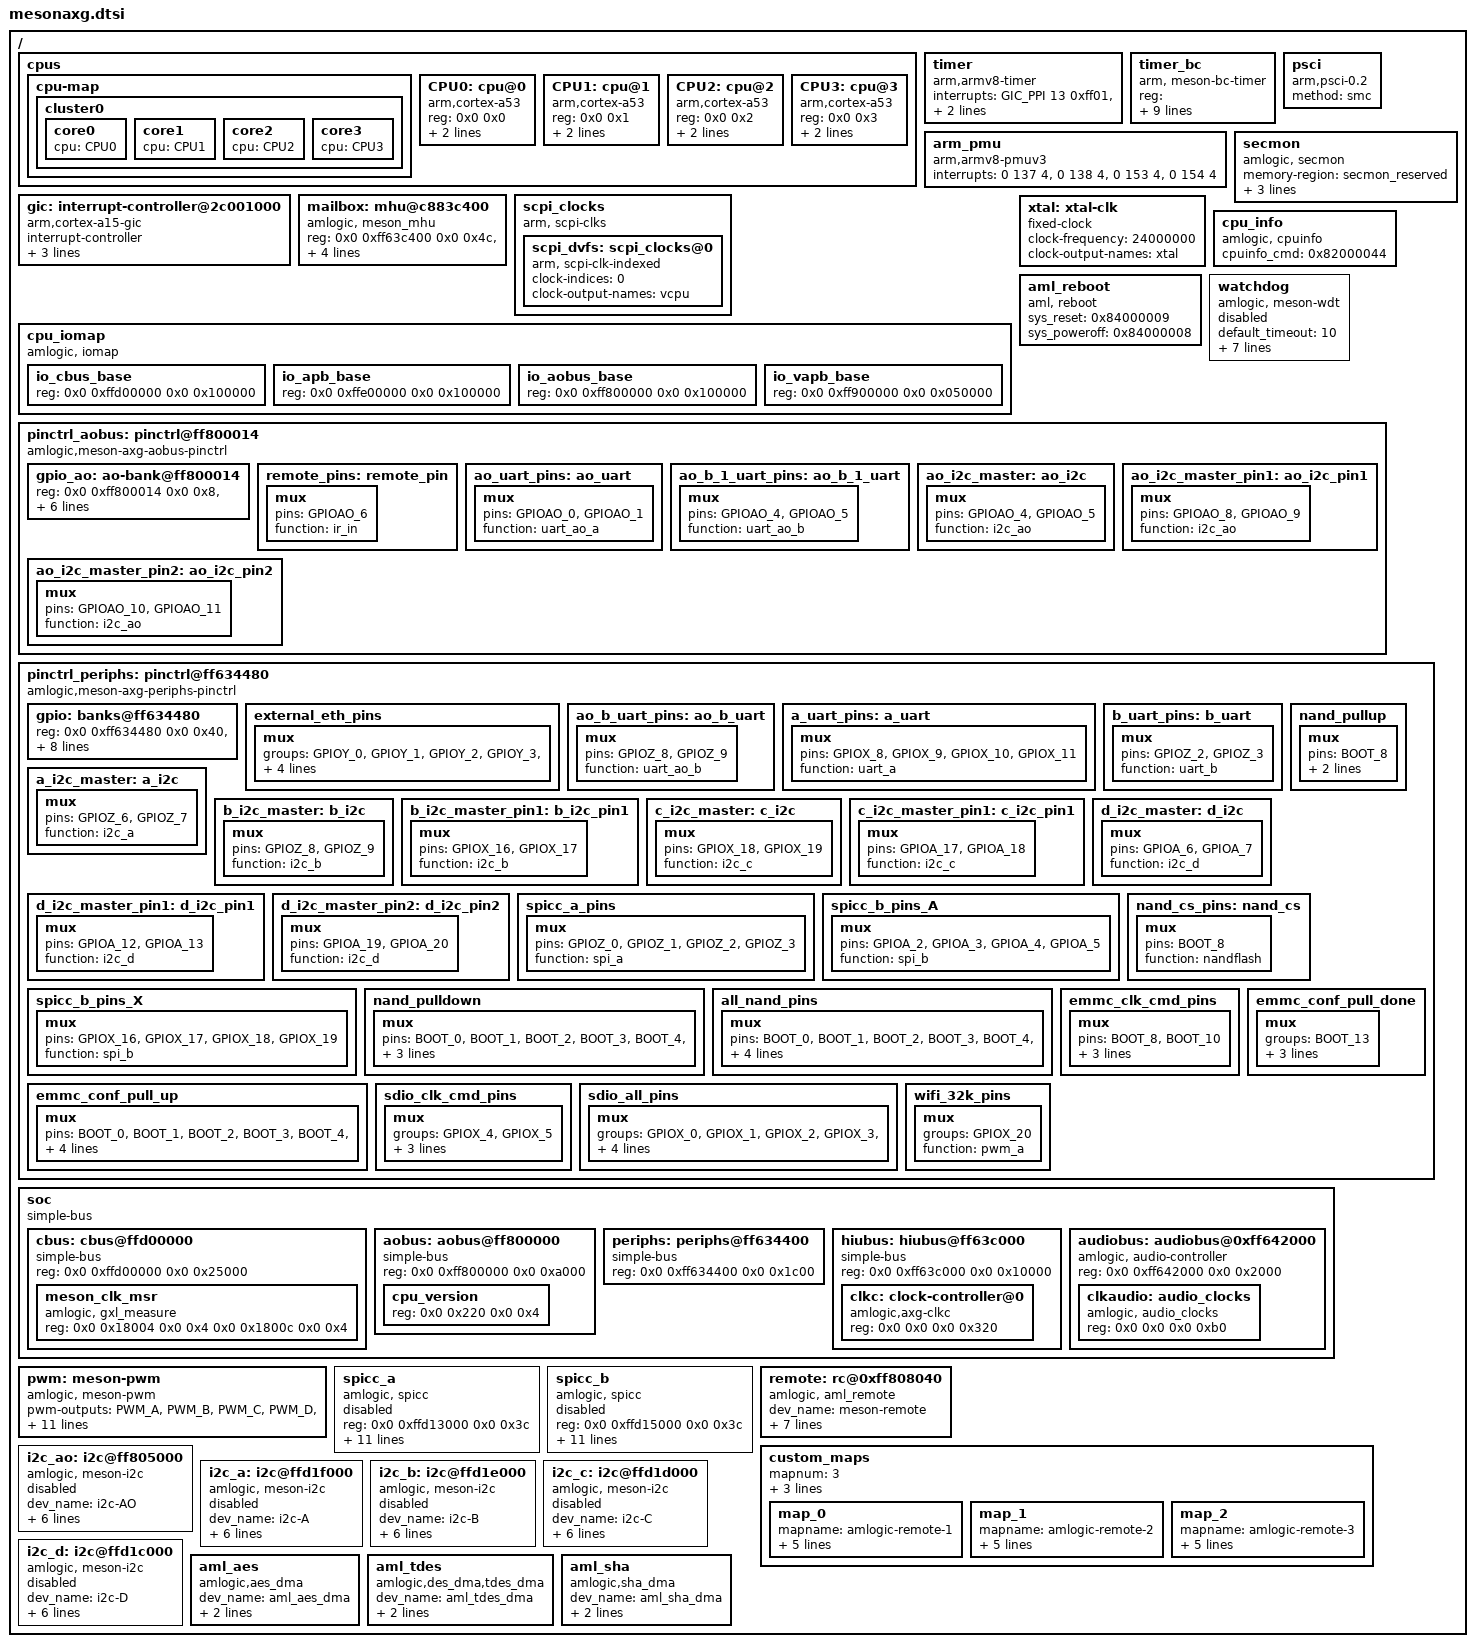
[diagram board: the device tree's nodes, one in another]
/*
 * arch/arm64/boot/dts/amlogic/mesonaxg.dtsi
 *
 * Copyright (C) 2017 Amlogic, Inc. All rights reserved.
 *
 * This program is free software; you can redistribute it and/or modify
 * it under the terms of the GNU General Public License as published by
 * the Free Software Foundation; either version 2 of the License, or
 * (at your option) any later version.
 *
 * This program is distributed in the hope that it will be useful, but WITHOUT
 * ANY WARRANTY; without even the implied warranty of MERCHANTABILITY or
 * FITNESS FOR A PARTICULAR PURPOSE.  See the GNU General Public License for
 * more details.
 *
 */

#include <dt-bindings/interrupt-controller/arm-gic.h>
#include <dt-bindings/clock/amlogic,axg-clkc.h>
#include <dt-bindings/clock/amlogic,axg-audio-clk.h>
#include <dt-bindings/gpio/mesonaxg-gpio.h>
#include <dt-bindings/pwm/pwm.h>
#include <dt-bindings/pwm/meson.h>
#include <dt-bindings/gpio/gpio.h>
#include <dt-bindings/input/input.h>
#include <dt-bindings/input/meson_rc.h>

/ {
	cpus:cpus {
		#address-cells = <2>;
		#size-cells = <0>;

		cpu-map {
			cluster0:cluster0 {
				core0 {
					cpu = <&CPU0>;
				};
				core1 {
					cpu = <&CPU1>;
				};
				core2 {
					cpu = <&CPU2>;
				};
				core3 {
					cpu = <&CPU3>;
				};
			};
		};
		CPU0:cpu@0 {
			device_type = "cpu";
			compatible = "arm,cortex-a53","arm,armv8";
			reg = <0x0 0x0>;
			enable-method = "psci";
			clocks = <&scpi_dvfs 0>;
			clock-names = "cpu-cluster.0";
			//cpu-idle-states = <&SYSTEM_SLEEP_0>;
			/*cpu-idle-states = <&CPU_SLEEP_0 &SYSTEM_SLEEP_0>;*/
		};

		CPU1:cpu@1 {
			device_type = "cpu";
			compatible = "arm,cortex-a53","arm,armv8";
			reg = <0x0 0x1>;
			enable-method = "psci";
			clocks = <&scpi_dvfs 0>;
			clock-names = "cpu-cluster.0";
			//cpu-idle-states = <&SYSTEM_SLEEP_0>;
			/*cpu-idle-states = <&CPU_SLEEP_0 &SYSTEM_SLEEP_0>;*/
		};
		CPU2:cpu@2 {
			device_type = "cpu";
			compatible = "arm,cortex-a53","arm,armv8";
			reg = <0x0 0x2>;
			enable-method = "psci";
			clocks = <&scpi_dvfs 0>;
			clock-names = "cpu-cluster.0";
			//cpu-idle-states = <&SYSTEM_SLEEP_0>;
			/*cpu-idle-states = <&CPU_SLEEP_0 &SYSTEM_SLEEP_0>;*/
		};

		CPU3:cpu@3 {
			device_type = "cpu";
			compatible = "arm,cortex-a53","arm,armv8";
			reg = <0x0 0x3>;
			enable-method = "psci";
			clocks = <&scpi_dvfs 0>;
			clock-names = "cpu-cluster.0";
			//cpu-idle-states = <&SYSTEM_SLEEP_0>;
			/*cpu-idle-states = <&CPU_SLEEP_0 &SYSTEM_SLEEP_0>;*/
		};

	};

	timer {
		compatible = "arm,armv8-timer";
		interrupts = <GIC_PPI 13 0xff01>,
			     <GIC_PPI 14 0xff01>,
			     <GIC_PPI 11 0xff01>,
			     <GIC_PPI 10 0xff01>;
	};
	timer_bc {
		compatible = "arm, meson-bc-timer";
		reg=   <0x0 0xffd0f190 0x0 0x4 0x0 0xffd0f194 0x0 0x4>;
		timer_name = "Meson TimerF";
		clockevent-rating=<300>;
		clockevent-shift=<20>;
		clockevent-features=<0x23>;
		interrupts = <0 60 1>;
		bit_enable=<16>;
		bit_mode=<12>;
		bit_resolution=<0>;
	};
	arm_pmu {
		compatible = "arm,armv8-pmuv3";
		interrupts = <0 137 4>,
			     <0 138 4>,
			     <0 153 4>,
			     <0 154 4>;
	};

	gic: interrupt-controller@2c001000 {
		compatible = "arm,cortex-a15-gic", "arm,cortex-a9-gic";
		#interrupt-cells = <3>;
		#address-cells = <0>;
		interrupt-controller;
		reg = <0x0 0xffc01000 0 0x1000>,
		      <0x0 0xffc02000 0 0x0100>;
		interrupts = <GIC_PPI 9 0xf04>;
	};

	psci {
		compatible = "arm,psci-0.2";
		method = "smc";
	};

	secmon {
		compatible = "amlogic, secmon";
		memory-region = <&secmon_reserved>;
		in_base_func = <0x82000020>;
		out_base_func = <0x82000021>;
		reserve_mem_size = <0x00300000>;
	};

	mailbox: mhu@c883c400 {
		compatible = "amlogic, meson_mhu";
		reg = <0x0 0xff63c400 0x0 0x4c>,   /* MHU registers */
		      <0x0 0xfffd3000 0x0 0x800>;   /* Payload area */
		interrupts = <0 209 1>,   /* low priority interrupt */
			     <0 210 1>;   /* high priority interrupt */
		#mbox-cells = <1>;
		mbox-names = "cpu_to_scp_low", "cpu_to_scp_high";
		mboxes = <&mailbox 0 &mailbox 1>;
	};

	scpi_clocks {
		compatible = "arm, scpi-clks";

		scpi_dvfs: scpi_clocks@0 {
			compatible = "arm, scpi-clk-indexed";
			#clock-cells = <1>;
			clock-indices = <0>;
			clock-output-names = "vcpu";
		};

	};

	cpu_iomap {
		compatible = "amlogic, iomap";
		#address-cells=<2>;
		#size-cells=<2>;
		ranges;
		io_cbus_base {
			reg = <0x0 0xffd00000 0x0 0x100000>;
		};
		io_apb_base {
			reg = <0x0 0xffe00000 0x0 0x100000>;
		};
		io_aobus_base {
			reg = <0x0 0xff800000 0x0 0x100000>;
		};
		io_vapb_base {
			reg = <0x0 0xff900000 0x0 0x050000>;
		};
	};

	xtal: xtal-clk {
		compatible = "fixed-clock";
		clock-frequency = <24000000>;
		clock-output-names = "xtal";
		#clock-cells = <0>;
	};

	cpu_info {
		compatible = "amlogic, cpuinfo";
		status = "okay";
		cpuinfo_cmd = <0x82000044>;
	};
	aml_reboot{
		compatible = "aml, reboot";
		sys_reset = <0x84000009>;
		sys_poweroff = <0x84000008>;
	};

	watchdog {
		compatible = "amlogic, meson-wdt";
		status = "disabled";
		default_timeout=<10>;
		reset_watchdog_method=<1>; /* 0:sysfs,1:kernel */
		reset_watchdog_time=<2>;
		shutdown_timeout=<10>;
		firmware_timeout=<6>;
		suspend_timeout=<6>;
		reg = <0x0 0xffd0f0d0 0x0 0x10>;
		clock-names = "xtal";
		clocks = <&xtal>;
	};

	pinctrl_aobus: pinctrl@ff800014{
		compatible = "amlogic,meson-axg-aobus-pinctrl";
		#address-cells = <2>;
		#size-cells = <2>;
		ranges;

		gpio_ao: ao-bank@ff800014{
			reg = <0x0 0xff800014 0x0 0x8>,
				  <0x0 0xff80002c 0x0 0x4>,
				  <0x0 0xff800024 0x0 0x8>,
				  <0x0 0xff800084 0x0 0x4>;
			interrupts = <0 200 1>,
				<0 201 1>;
			reg-names = "mux", "pull", "gpio", "irq";
			gpio-controller;
			#gpio-cells = <2>;
			interrupt-controller;
			#interrupt-cells = <2>;
		};
	};

	pinctrl_periphs: pinctrl@ff634480{
		compatible = "amlogic,meson-axg-periphs-pinctrl";
		#address-cells = <2>;
		#size-cells = <2>;
		ranges;

		gpio: banks@ff634480{
			reg = <0x0 0xff634480 0x0 0x40>,
				  <0x0 0xff6344e8 0x0 0x14>,
				  <0x0 0xff634520 0x0 0x14>,
				  <0x0 0xff634430 0x0 0x3c>,
				  <0x0 0xffd0f080 0x0 0x10>;
			interrupts = <0 64 1>,
				<0 65 1>,
				<0 66 1>,
				<0 67 1>,
				<0 68 1>,
				<0 69 1>,
				<0 70 1>,
				<0 71 1>;
			reg-names = "mux",
				"pull",
				"pull-enable",
				"gpio",
				"irq";
			gpio-controller;
			#gpio-cells = <2>;
			interrupt-controller;
			#interrupt-cells = <2>;
		};
	};


	soc {
		compatible = "simple-bus";
		#address-cells = <2>;
		#size-cells = <2>;
		ranges;

		cbus: cbus@ffd00000 {
			compatible = "simple-bus";
			reg = <0x0 0xffd00000 0x0 0x25000>;
			#address-cells = <2>;
			#size-cells = <2>;
			ranges = <0x0 0x0 0x0 0xffd00000 0x0 0x25000>;

			meson_clk_msr {
				compatible = "amlogic, gxl_measure";
				reg = <0x0 0x18004 0x0 0x4
		       0x0 0x1800c 0x0 0x4>;
			};
		}; /* end of cbus */

		aobus: aobus@ff800000 {
			compatible = "simple-bus";
			reg = <0x0 0xff800000 0x0 0xa000>;
			#address-cells = <2>;
			#size-cells = <2>;
			ranges = <0x0 0x0 0x0 0xff800000 0x0 0xa000>;

			cpu_version {
				reg=<0x0 0x220 0x0 0x4>;
			};
		};/* end of aobus */

		periphs: periphs@ff634400 {
			compatible = "simple-bus";
			reg = <0x0 0xff634400 0x0 0x1c00>;
			#address-cells = <2>;
			#size-cells = <2>;
			ranges = <0x0 0x0 0x0 0xff634400 0x0 0x1c00>;

		};/* end of periphs */

		hiubus: hiubus@ff63c000 {
			compatible = "simple-bus";
			reg = <0x0 0xff63c000 0x0 0x10000>;
			#address-cells = <2>;
			#size-cells = <2>;
			ranges = <0x0 0x0 0x0 0xff63c000 0x0 0x10000>;

			clkc: clock-controller@0 {
				compatible = "amlogic,axg-clkc";
				#clock-cells = <1>;
				reg = <0x0 0x0 0x0 0x320>;
			};
		};/* end of hiubus*/

		audiobus: audiobus@0xff642000 {
			compatible = "amlogic, audio-controller", "simple-bus";
			reg = <0x0 0xff642000 0x0 0x2000>;
			#address-cells = <2>;
			#size-cells = <2>;
			ranges = <0x0 0x0 0x0 0xff642000 0x0 0x2000>;
			clkaudio: audio_clocks {
				compatible = "amlogic, audio_clocks";
				#clock-cells = <1>;
				reg = <0x0 0x0 0x0 0xb0>;
			};
		};/* end of audiobus*/
	}; /* end of soc*/

	pwm:meson-pwm {
		compatible = "amlogic, meson-pwm";
		status = "okay";
		#pwm-cells = <2>;
		pwm-outputs = <PWM_A>,<PWM_B>,<PWM_C>,<PWM_D>,
		<PWM_AO_A>,<PWM_AO_B>,<PWM_AO_C>,<PWM_AO_D>,
		<PWM_A2>,<PWM_B2>,<PWM_C2>,<PWM_D2>,<PWM_AO_A2>,
		<PWM_AO_B2>,<PWM_AO_C2>,<PWM_AO_D2>;
		reg = <0x0 0xffd1b000  0x0 0x20>,
				<0x0 0xffd1a000  0x0 0x20>,
				<0x0 0xff807000  0x0 0x20>,
				<0x0 0xff802000  0x0 0x20>;
		clocks = <&xtal>,
				<&clkc CLKID_PLL_VID_NOT>,
				<&clkc CLKID_FCLK_DIV4>,
				<&clkc CLKID_FCLK_DIV3>;
		clock-names = "xtal",
					"vid_pll_clk",
					"fclk_div4",
					"fclk_div3";
		clock-select = <XTAL>,<XTAL>,<XTAL>,<XTAL>,
						<XTAL>,<XTAL>,<XTAL>,<XTAL>;
		/*all channels use the default clock source XTAL_CLK*/
		/*and you can shoose it in file dt-bindings/pwm/meson.h*/
	};

	spicc_a:spicc_a {
		compatible = "amlogic, spicc";
		status = "disabled";
		reg = <0x0 0xffd13000 0x0 0x3c>;
		clocks = <&clkc CLKID_SPICC0>,
			<&clkc CLKID_SPICC_COMP>;
		clock-names = "spicc_clk",
			"cts_spicc_hclk";
		interrupts = <0 81 1>;
		device_id = <0>;
		enhance = <1>;
		pinctrl-names= "default";
		pinctrl-0=<&spicc_a_pins>;
		dma_tx_threshold = <3>;
		dma_rx_threshold = <3>;
		dma_num_per_read_burst = <3>;
		dma_num_per_write_burst = <3>;
		ssctl = <0>;
	};

	spicc_b:spicc_b {
		compatible = "amlogic, spicc";
		status = "disabled";
		reg = <0x0 0xffd15000 0x0 0x3c>;
		clocks = <&clkc CLKID_SPICC1>,
			<&clkc CLKID_SPICC_COMP>;
		clock-names = "spicc_clk",
			"cts_spicc_hclk";
		interrupts = <0 82 1>;
		device_id = <1>;
		enhance = <1>;
		pinctrl-names= "default";
		pinctrl-0=<&spicc_b_pins_X>;
		dma_tx_threshold = <3>;
		dma_rx_threshold = <3>;
		dma_num_per_read_burst = <3>;
		dma_num_per_write_burst = <3>;
		ssctl = <0>;
	};

	remote:rc@0xff808040 {
		compatible = "amlogic, aml_remote";
		dev_name = "meson-remote";
		reg = <0x0 0xff808040 0x00 0x44>, /*Multi-format IR controller*/
			<0x0 0xff808000 0x00 0x20>; /*Legacy IR controller*/
		status = "okay";
		protocol = <REMOTE_TYPE_NEC>;
		interrupts = <0 196 1>;
		pinctrl-names = "default";
		pinctrl-0 = <&remote_pins>;
		map = <&custom_maps>;
		max_frame_time = <200>; /*set software decoder max frame time*/
	};

	custom_maps:custom_maps {
		mapnum = <3>;
		map0 = <&map_0>;
		map1 = <&map_1>;
		map2 = <&map_2>;
		map_0: map_0{
			mapname = "amlogic-remote-1";
			customcode = <0xfb04>;
			release_delay = <80>;
			size  = <50>;   /*keymap size*/
			keymap = <REMOTE_KEY(0x47, KEY_0)
				REMOTE_KEY(0x13, KEY_1)
				REMOTE_KEY(0x10, KEY_2)
				REMOTE_KEY(0x11, KEY_3)
				REMOTE_KEY(0x0F, KEY_4)
				REMOTE_KEY(0x0C, KEY_5)
				REMOTE_KEY(0x0D, KEY_6)
				REMOTE_KEY(0x0B, KEY_7)
				REMOTE_KEY(0x08, KEY_8)
				REMOTE_KEY(0x09, KEY_9)
				REMOTE_KEY(0x5C, KEY_RIGHTCTRL)
				REMOTE_KEY(0x51, KEY_F3)
				REMOTE_KEY(0x50, KEY_F4)
				REMOTE_KEY(0x40, KEY_F5)
				REMOTE_KEY(0x4d, KEY_F6)
				REMOTE_KEY(0x43, KEY_F7)
				REMOTE_KEY(0x17, KEY_F8)
				REMOTE_KEY(0x00, KEY_F9)
				REMOTE_KEY(0x01, KEY_F10)
				REMOTE_KEY(0x16, KEY_F11)
				REMOTE_KEY(0x49, KEY_BACKSPACE)
				REMOTE_KEY(0x06, KEY_PROPS)
				REMOTE_KEY(0x14, KEY_UNDO)
				REMOTE_KEY(0x44, KEY_UP)
				REMOTE_KEY(0x1D, KEY_DOWN)
				REMOTE_KEY(0x1C, KEY_LEFT)
				REMOTE_KEY(0x48, KEY_RIGHT)
				REMOTE_KEY(0x53, KEY_LEFTMETA)
				REMOTE_KEY(0x45, KEY_PAGEUP)
				REMOTE_KEY(0x19, KEY_PAGEDOWN)
				REMOTE_KEY(0x52, KEY_PAUSE)
				REMOTE_KEY(0x05, KEY_HANGEUL)
				REMOTE_KEY(0x59, KEY_HANJA)
				REMOTE_KEY(0x1b, KEY_SCALE)
				REMOTE_KEY(0x04, KEY_KPCOMMA)
				REMOTE_KEY(0x1A, KEY_POWER)
				REMOTE_KEY(0x0A, KEY_TAB)
				REMOTE_KEY(0x0e, KEY_MUTE)
				REMOTE_KEY(0x1F, KEY_HOME)
				REMOTE_KEY(0x1e, KEY_FRONT)
				REMOTE_KEY(0x07, KEY_COPY)
				REMOTE_KEY(0x12, KEY_OPEN)
				REMOTE_KEY(0x54, KEY_PASTE)
				REMOTE_KEY(0x02, KEY_FIND)
				REMOTE_KEY(0x4f, KEY_A)
				REMOTE_KEY(0x42, KEY_B)
				REMOTE_KEY(0x5d, KEY_C)
				REMOTE_KEY(0x4c, KEY_D)
				REMOTE_KEY(0x58, KEY_CUT)
				REMOTE_KEY(0x55, KEY_CALC)>;
		};
		map_1: map_1{
			mapname = "amlogic-remote-2";
			customcode = <0xfe01>;
			release_delay = <80>;
			size  = <53>;
			keymap = <REMOTE_KEY(0x01, KEY_1)
				REMOTE_KEY(0x02, KEY_2)
				REMOTE_KEY(0x03, KEY_3)
				REMOTE_KEY(0x04, KEY_4)
				REMOTE_KEY(0x05, KEY_5)
				REMOTE_KEY(0x06, KEY_6)
				REMOTE_KEY(0x07, KEY_7)
				REMOTE_KEY(0x08, KEY_8)
				REMOTE_KEY(0x09, KEY_9)
				REMOTE_KEY(0x0a, KEY_0)
				REMOTE_KEY(0x1F, KEY_FN_F1)
				REMOTE_KEY(0x15, KEY_MENU)
				REMOTE_KEY(0x16, KEY_TAB)
				REMOTE_KEY(0x0c, KEY_CHANNELUP)
				REMOTE_KEY(0x0d, KEY_CHANNELDOWN)
				REMOTE_KEY(0x0e, KEY_VOLUMEUP)
				REMOTE_KEY(0x0f, KEY_VOLUMEDOWN)
				REMOTE_KEY(0x11, KEY_HOME)
				REMOTE_KEY(0x1c, KEY_RIGHT)
				REMOTE_KEY(0x1b, KEY_LEFT)
				REMOTE_KEY(0x19, KEY_UP)
				REMOTE_KEY(0x1a, KEY_DOWN)
				REMOTE_KEY(0x1d, KEY_ENTER)
				REMOTE_KEY(0x17, KEY_MUTE)
				REMOTE_KEY(0x49, KEY_FINANCE)
				REMOTE_KEY(0x43, KEY_BACK)
				REMOTE_KEY(0x12, KEY_FN_F4)
				REMOTE_KEY(0x14, KEY_FN_F5)
				REMOTE_KEY(0x18, KEY_FN_F6)
				REMOTE_KEY(0x59, KEY_INFO)
				REMOTE_KEY(0x5a, KEY_STOPCD)
				REMOTE_KEY(0x10, KEY_POWER)
				REMOTE_KEY(0x42, KEY_PREVIOUSSONG)
				REMOTE_KEY(0x44, KEY_NEXTSONG)
				REMOTE_KEY(0x1e, KEY_REWIND)
				REMOTE_KEY(0x4b, KEY_FASTFORWARD)
				REMOTE_KEY(0x58, KEY_PLAYPAUSE)
				REMOTE_KEY(0x46, KEY_PROPS)
				REMOTE_KEY(0x40, KEY_UNDO)
				REMOTE_KEY(0x38, KEY_SCROLLLOCK)
				REMOTE_KEY(0x57, KEY_FN)
				REMOTE_KEY(0x5b, KEY_FN_ESC)
				REMOTE_KEY(0x54, KEY_RED)
				REMOTE_KEY(0x4c, KEY_GREEN)
				REMOTE_KEY(0x4e, KEY_YELLOW)
				REMOTE_KEY(0x55, KEY_BLUE)
				REMOTE_KEY(0x53, KEY_BLUETOOTH)
				REMOTE_KEY(0x52, KEY_WLAN)
				REMOTE_KEY(0x39, KEY_CAMERA)
				REMOTE_KEY(0x41, KEY_SOUND)
				REMOTE_KEY(0x0b, KEY_QUESTION)
				REMOTE_KEY(0x00, KEY_CHAT)
				REMOTE_KEY(0x13, KEY_SEARCH)>;
		};
		map_2: map_2{
			mapname = "amlogic-remote-3";
			customcode = <0xbd02>;
			release_delay = <80>;
			size  = <17>;
			keymap = <REMOTE_KEY(0xca,103)
			REMOTE_KEY(0xd2,108)
			REMOTE_KEY(0x99,105)
			REMOTE_KEY(0xc1,106)
			REMOTE_KEY(0xce,97)
			REMOTE_KEY(0x45,116)
			REMOTE_KEY(0xc5,133)
			REMOTE_KEY(0x80,113)
			REMOTE_KEY(0xd0,15)
			REMOTE_KEY(0xd6,125)
			REMOTE_KEY(0x95,102)
			REMOTE_KEY(0xdd,104)
			REMOTE_KEY(0x8c,109)
			REMOTE_KEY(0x89,131)
			REMOTE_KEY(0x9c,130)
			REMOTE_KEY(0x9a,120)
			REMOTE_KEY(0xcd,121)>;
		};
	};

	i2c_ao: i2c@ff805000{ /*I2C-AO*/
		compatible = "amlogic, meson-i2c";
		dev_name = "i2c-AO";
		status = "disabled";
		reg = <0x0 0xff805000 0x0 0x1d>;
		device_id = <0>;
		pinctrl-names="default";
		pinctrl-0=<&ao_i2c_master>;
		#address-cells = <1>;
		#size-cells = <0>;
		use_pio = <0>;
		master_i2c_speed = <300000>;
		clocks = <&clkc CLKID_AO_I2C>;
		clock-names = "clk_i2c";
	};

	i2c_a: i2c@ffd1f000 { /*I2C-A*/
		compatible = "amlogic, meson-i2c";
		dev_name = "i2c-A";
		status = "disabled";
		reg = <0x0 0xffd1f000 0x0 0x20>;
		device_id = <1>;
		pinctrl-names="default";
		pinctrl-0=<&a_i2c_master>;/*p200 i2c-A multiplex with usb PWR*/
		#address-cells = <1>;
		#size-cells = <0>;
		use_pio = <0>;
		master_i2c_speed = <300000>;
		clocks = <&clkc CLKID_I2C>;
		clock-names = "clk_i2c";
	};

	i2c_b: i2c@ffd1e000 { /*I2C-B*/
		compatible = "amlogic, meson-i2c";
		dev_name = "i2c-B";
		status = "disabled";
		reg = <0x0 0xffd1e000 0x0 0x20>;
		device_id = <2>;
		pinctrl-names="default";
		pinctrl-0=<&b_i2c_master>;
		#address-cells = <1>;
		#size-cells = <0>;
		use_pio = <0>;
		master_i2c_speed = <300000>;
		clocks = <&clkc CLKID_I2C>;
		clock-names = "clk_i2c";
	};

	i2c_c: i2c@ffd1d000 { /*I2C-C*/
		compatible = "amlogic, meson-i2c";
		dev_name = "i2c-C";
		status = "disabled";
		reg = <0x0 0xffd1d000 0x0 0x20>;
		device_id = <3>;
		pinctrl-names="default";
		pinctrl-0=<&c_i2c_master>;
		#address-cells = <1>;
		#size-cells = <0>;
		use_pio = <0>;
		master_i2c_speed = <300000>;
		clocks = <&clkc CLKID_I2C>;
		clock-names = "clk_i2c";
	};

	i2c_d: i2c@ffd1c000 { /*I2C-D*/
		compatible = "amlogic, meson-i2c";
		dev_name = "i2c-D";
		status = "disabled";
		reg = <0x0 0xffd1c000 0x0 0x20>;
		device_id = <4>;
		pinctrl-names="default";
		pinctrl-0=<&d_i2c_master>;
		#address-cells = <1>;
		#size-cells = <0>;
		use_pio = <0>;
		master_i2c_speed = <300000>;
		clocks = <&clkc CLKID_I2C>;
		clock-names = "clk_i2c";
	};

	aml_aes {
		compatible = "amlogic,aes_dma";
		dev_name = "aml_aes_dma";
		status = "okay";
		interrupts = <0 180 1 0 181 1>;
		reg = <0x0 0xff63e000 0x0 0x48>;
	};

	aml_tdes {
		compatible = "amlogic,des_dma,tdes_dma";
		dev_name = "aml_tdes_dma";
		status = "okay";
		interrupts = <0 180 1 0 181 1>;
		reg = <0x0 0xff63e000 0x0 0x48>;
	};

	aml_sha {
		compatible = "amlogic,sha_dma";
		dev_name = "aml_sha_dma";
		status = "okay";
		interrupts = <0 180 1 0 181 1>;
		reg = <0x0 0xff63e000 0x0 0x48>;
	};
};/* end of / */

&pinctrl_aobus {
	remote_pins:remote_pin {
		mux {
			pins = "GPIOAO_6";
			function = "ir_in";
		};
	};

	ao_uart_pins:ao_uart {
			mux {
				pins = "GPIOAO_0",
					"GPIOAO_1";
				function = "uart_ao_a";
			};
		};

	ao_b_1_uart_pins:ao_b_1_uart {
		mux {
				pins = "GPIOAO_4",
					"GPIOAO_5";
				function = "uart_ao_b";
		};
	};

	ao_i2c_master:ao_i2c{
		mux {
			pins = "GPIOAO_4","GPIOAO_5";
			function = "i2c_ao";
		};
	};

	ao_i2c_master_pin1:ao_i2c_pin1{
		mux {
			pins = "GPIOAO_8","GPIOAO_9";
			function = "i2c_ao";
		};
	};

	ao_i2c_master_pin2:ao_i2c_pin2{
		mux {
			pins = "GPIOAO_10","GPIOAO_11";
			function = "i2c_ao";
		};
	};
}; /* end of pinctrl_aobus */

&pinctrl_periphs {
	external_eth_pins:external_eth_pins {
		mux {
			groups = "GPIOY_0",
				"GPIOY_1",
				"GPIOY_2",
				"GPIOY_3",
				"GPIOY_4",
				"GPIOY_5",
				"GPIOY_6",
				"GPIOY_7",
				"GPIOY_8",
				"GPIOY_9",
				"GPIOY_10",
				"GPIOY_11",
				"GPIOY_12",
				"GPIOY_13";
			function = "eth";
		};
	};
	ao_b_uart_pins:ao_b_uart {
		mux {
				pins = "GPIOZ_8",
					"GPIOZ_9";
				function = "uart_ao_b";
		};
	};

	a_uart_pins:a_uart {
		mux {
			pins = "GPIOX_8",
				"GPIOX_9",
				"GPIOX_10",
				"GPIOX_11";
			function = "uart_a";
		};
	};

	b_uart_pins:b_uart {
		mux {
			pins = "GPIOZ_2",
				"GPIOZ_3";
			function = "uart_b";
		};
	};

	a_i2c_master:a_i2c {
		mux {
			pins = "GPIOZ_6","GPIOZ_7";
			function = "i2c_a";
		};
	};

	b_i2c_master:b_i2c {
		mux {
			pins = "GPIOZ_8","GPIOZ_9";
			function = "i2c_b";
		};
	};

	b_i2c_master_pin1:b_i2c_pin1 {
		mux {
			pins = "GPIOX_16","GPIOX_17";
			function = "i2c_b";
		};
	};

	c_i2c_master:c_i2c {
		mux {
			pins = "GPIOX_18","GPIOX_19";
			function = "i2c_c";
		};
	};

	c_i2c_master_pin1:c_i2c_pin1 {
		mux {
			pins = "GPIOA_17","GPIOA_18";
			function = "i2c_c";
		};
	};

	d_i2c_master:d_i2c {
		mux {
			pins = "GPIOA_6","GPIOA_7";
			function = "i2c_d";
		};
	};

	d_i2c_master_pin1:d_i2c_pin1 {
		mux {
			pins = "GPIOA_12","GPIOA_13";
			function = "i2c_d";
		};
	};

	d_i2c_master_pin2:d_i2c_pin2 {
		mux {
			pins = "GPIOA_19","GPIOA_20";
			function = "i2c_d";
		};
	};

	spicc_a_pins: spicc_a_pins{
		mux {
			pins = "GPIOZ_0","GPIOZ_1","GPIOZ_2","GPIOZ_3";
			function = "spi_a";
		};
	};
	spicc_b_pins_A: spicc_b_pins_A{
		mux {
			pins="GPIOA_2","GPIOA_3","GPIOA_4","GPIOA_5";
			function = "spi_b";
		};
	};
	spicc_b_pins_X: spicc_b_pins_X{
		mux {
			pins = "GPIOX_16","GPIOX_17","GPIOX_18","GPIOX_19";
			function = "spi_b";
		};
	};
	nand_pulldown: nand_pulldown {
		mux {
			pins = "BOOT_0",
				"BOOT_1",
				"BOOT_2",
				"BOOT_3",
				"BOOT_4",
				"BOOT_5",
				"BOOT_6",
				"BOOT_7",
				"BOOT_13";
			function = "nandflash";
			bias-pull-down;
		};
	};

	nand_pullup: nand_pullup {
		mux {
			pins = "BOOT_8";
			function = "nandflash";
			bias-pull-up;
		};
	};

	all_nand_pins: all_nand_pins {
		mux {
			pins =  "BOOT_0",
				"BOOT_1",
				"BOOT_2",
				"BOOT_3",
				"BOOT_4",
				"BOOT_5",
				"BOOT_6",
				"BOOT_7",
				"BOOT_8",
				"BOOT_9",
				"BOOT_10",
				"BOOT_11",
				"BOOT_12",
				"BOOT_13";
			function = "nandflash";
			input-enable;
		};
	};

	nand_cs_pins: nand_cs {
		mux {
			pins = "BOOT_8";
			function = "nandflash";
		};
	};

	emmc_clk_cmd_pins:emmc_clk_cmd_pins {
		mux {
			pins = "BOOT_8",
				"BOOT_10";
			function = "emmc";
			input-enable;
			bias-pull-up;
		};
	};


	emmc_conf_pull_up:emmc_conf_pull_up {
		mux {
			pins = "BOOT_0","BOOT_1","BOOT_2",
				"BOOT_3","BOOT_4","BOOT_5","BOOT_6",
				"BOOT_7","BOOT_8","BOOT_10";
			function = "emmc";
			input-enable;
			bias-pull-up;
		};
	};

	emmc_conf_pull_done:emmc_conf_pull_done {
		mux {
			groups = "BOOT_13";
			function = "emmc";
			input-enable;
			bias-pull-down;
		};
	};

	sdio_clk_cmd_pins:sdio_clk_cmd_pins {
		mux {
			groups = "GPIOX_4",
				"GPIOX_5";
			function = "sdio";
			input-enable;
			bias-pull-up;
		};
	};

	sdio_all_pins:sdio_all_pins {
		mux {
			groups = "GPIOX_0",
				"GPIOX_1",
				"GPIOX_2",
				"GPIOX_3",
				"GPIOX_4",
				"GPIOX_5";
			function = "sdio";
			input-enable;
			bias-pull-up;
		};
	};

	wifi_32k_pins:wifi_32k_pins {
		mux {
			groups ="GPIOX_20";
			function = "pwm_a";
		};
	};

}; /* end of pinctrl_periphs */

